# AM13E230x register map
Vendor: Texas Instruments; File version: Revised: 2025-12-26 17:30:06
CPU: CM33 r0p0, little endian, MPU, FPU, 4 interrupt priority bits
Registers are 32-bit, read-write, reset 0x0 unless marked. A register's access mark holds for its fields unless they carry their own. Offsets are from the block's base; [hi:lo] are bit positions; 'fields as' and 'values as' point back to an identical list.

## FACTORYREGION — Factory-programmed device data (read-only)
Base 0x60111000
0x00 TRACEID ro — Defined by TI, during ATE, based on wafer
  [31:0] DATA
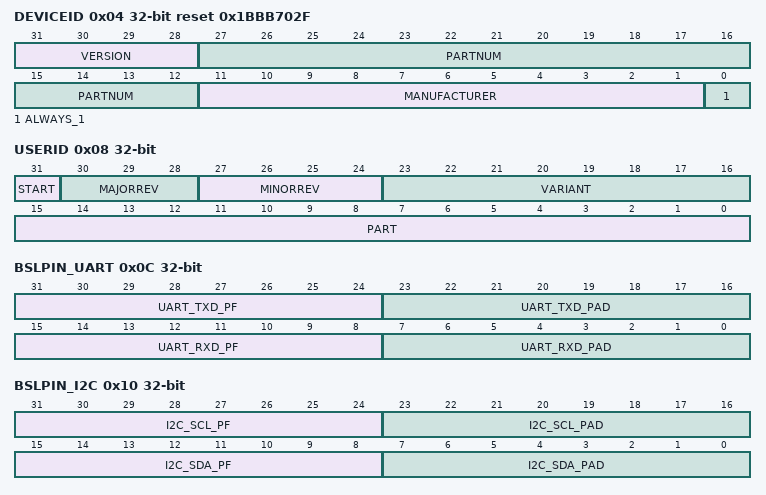
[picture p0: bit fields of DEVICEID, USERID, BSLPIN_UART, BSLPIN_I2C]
0x04 DEVICEID ro reset 0x1BBB702F
  [31:28] VERSION — Revision of the device. This field should change each time that the logic or mask set of the device is revised.
  [27:12] PARTNUM — Part number of the device.
  [11:1] MANUFACTURER — TI's JEDEC bank and company code, which is: 00000010111b
  [0] ALWAYS_1 — This is always 1
0x08 USERID ro — Defined by TI, depending on device spin
  [31] START
  [30:28] MAJORREV — Monotonic increasing value indicating a new revision of the SKU significant enough that users of the device may have to revise PCB or or software design
  [27:24] MINORREV — Monotonic increasing value indicating a new revision of the SKU that preserves compatibility with lesser minorrev values. New capability may be introduced such that lesser minorrev numbers may not be compatible with greater if the new capability is used.
  [23:16] VARIANT — Bit pattern uniquely identifying a variant of a part. This is used to indicate memory or package variations of the same part number. This number shall be selected at random among the remaining numbers for the relevant combination of IDCODE.device and USERCODE.part such that the order of creation cannot be inferred by the number. The variant number does not encode specifics of the variant directly.
  [15:0] PART — Bit pattern that uniquely identifying a part. This is used to identify the specific part based on the die identified in DEVICEID.device. This number shall be selected at random among the remaining numbers for DEVICEID.device such that the order of creation cannot be inferred by the number. This value does not encode the part number directly.
0x0C BSLPIN_UART ro — BSL UART Pin Configuration
  [31:24] UART_TXD_PF — UART TXD Pin Function Selection Value
  [23:16] UART_TXD_PAD — UART TXD Pin used by BSL
  [15:8] UART_RXD_PF — UART RXD Pin Function Selection Value
  [7:0] UART_RXD_PAD — UART RXD Pad used by BSL
0x10 BSLPIN_I2C ro — BSL I2C Pin Configuration
  [31:24] I2C_SCL_PF — I2C SCL Pin Function Selection Value
  [23:16] I2C_SCL_PAD — I2C SCL Pin used by BSL
  [15:8] I2C_SDA_PF — I2C SDA Pin Function Selection Value
  [7:0] I2C_SDA_PAD — I2C SDA Pin used by BSL
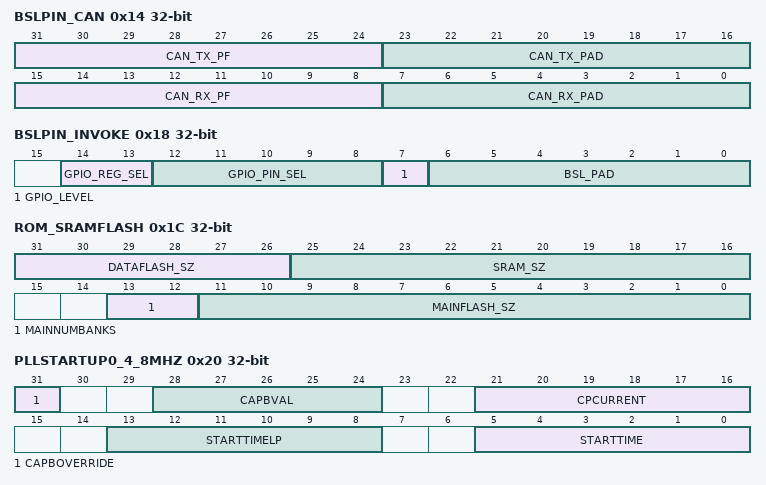
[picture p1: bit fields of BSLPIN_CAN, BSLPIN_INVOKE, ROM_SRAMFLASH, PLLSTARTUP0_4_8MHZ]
0x14 BSLPIN_CAN ro — BSL CAN Pin Configuration
  [31:24] CAN_TX_PF — MCAN TX Pin Function Selection Value
  [23:16] CAN_TX_PAD — MCAN TX Pin used by BSL
  [15:8] CAN_RX_PF — MCAN RX Pin Function Selection Value
  [7:0] CAN_RX_PAD — MCAN RX Pin used by BSL
0x18 BSLPIN_INVOKE ro — BSL Pin Invocation Configuration
  [14:13] GPIO_REG_SEL — GPIO Module Selection
  [12:8] GPIO_PIN_SEL — GPIO Pin Number in GPIO Module
  [7] GPIO_LEVEL — GPIO Level Configuration for BSL Invocation
  [6:0] BSL_PAD — BSL Invocation Pin Number
0x1C ROM_SRAMFLASH ro
  [31:26] DATAFLASH_SZ — The encoding of the field is that the value of the field is an integer to be interpreted as number of KBs. For eg: if the value of the field id 4, then it is 4KB, if the value is 32, then 32KB, and so on.
  [25:16] SRAM_SZ — The encoding of the field is that the value of the field is an integer to be interpreted as number of KBs. For eg: if the value of the field id 4, then it is 4KB, if the value is 32, then 32KB, and so on.
  [13:12] MAINNUMBANKS — Defines the number of main flash banks
  [11:0] MAINFLASH_SZ — The encoding of the field is that the value of the field is an integer to be interpreted as number of KBs. For eg: if the value of the field id 4, then it is 4KB, if the value is 32, then 32KB, and so on.
0x20 PLLSTARTUP0_4_8MHZ ro
  [31] CAPBOVERRIDE — Override Enable For Cap B
    0=DISABLE; 1=ENABLE
  [28:24] CAPBVAL — Override Value for Cap B
  [21:16] CPCURRENT — Charge Pump Current
  [13:8] STARTTIMELP — Startup time from Low Power Exit to Locked Clock in resolution of 1usec
  [5:0] STARTTIME — Startup time from Enable to Locked Clock in resolution of 1usec
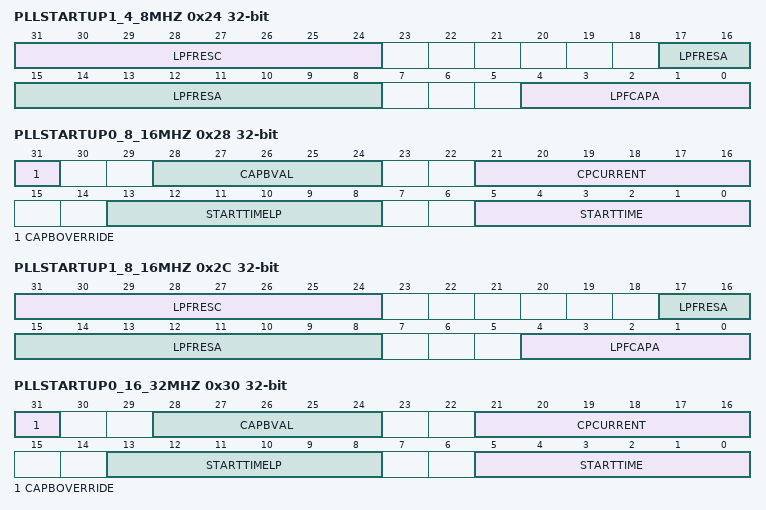
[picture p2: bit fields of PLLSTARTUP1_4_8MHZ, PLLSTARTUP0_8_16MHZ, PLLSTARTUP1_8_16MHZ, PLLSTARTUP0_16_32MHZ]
0x24 PLLSTARTUP1_4_8MHZ ro
  [31:24] LPFRESC — Loop Filter Res C
  [17:8] LPFRESA — Loop Filter Res A
  [4:0] LPFCAPA — Loop Filter Cap A
0x28 PLLSTARTUP0_8_16MHZ ro
  fields as PLLSTARTUP0_4_8MHZ
0x2C PLLSTARTUP1_8_16MHZ ro
  fields as PLLSTARTUP1_4_8MHZ
0x30 PLLSTARTUP0_16_32MHZ ro
  fields as PLLSTARTUP0_4_8MHZ
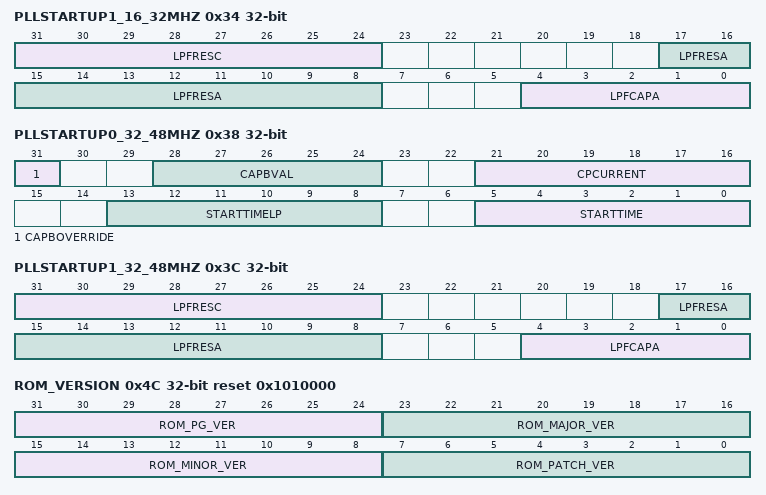
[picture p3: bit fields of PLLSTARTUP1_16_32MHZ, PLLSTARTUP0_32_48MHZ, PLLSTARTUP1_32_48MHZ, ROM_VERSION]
0x34 PLLSTARTUP1_16_32MHZ ro
  fields as PLLSTARTUP1_4_8MHZ
0x38 PLLSTARTUP0_32_48MHZ ro
  fields as PLLSTARTUP0_4_8MHZ
0x3C PLLSTARTUP1_32_48MHZ ro
  fields as PLLSTARTUP1_4_8MHZ
0x40 TEMP_SENSE0 ro
  [31:0] DATA
0x44 BOOTCRC ro
  [31:0] DATA
0x4C ROM_VERSION ro reset 0x1010000
  [31:24] ROM_PG_VER, [23:16] ROM_MAJOR_VER, [15:8] ROM_MINOR_VER, [7:0] ROM_PATCH_VER
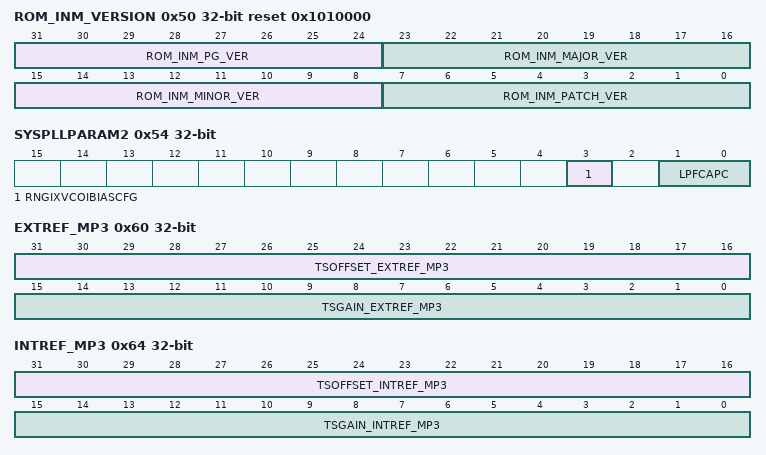
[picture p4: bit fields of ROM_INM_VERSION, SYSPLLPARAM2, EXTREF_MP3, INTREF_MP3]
0x50 ROM_INM_VERSION ro reset 0x1010000
  [31:24] ROM_INM_PG_VER, [23:16] ROM_INM_MAJOR_VER, [15:8] ROM_INM_MINOR_VER, [7:0] ROM_INM_PATCH_VER
0x54 SYSPLLPARAM2 ro
  [3] RNGIXVCOIBIASCFG, [1:0] LPFCAPC
0x58 SYSPLLLDOCTL ro
  [15:0] LDOCTLLOWV
0x5C SYSPLLLDOPROG ro
  [2:0] LDOVOUTPROGLOWV
0x60 EXTREF_MP3 ro — External Reference MP3 Temp Sense
  [31:16] TSOFFSET_EXTREF_MP3 — Temperature sensor offset is recorded here
  [15:0] TSGAIN_EXTREF_MP3 — Temperature sensor gain is recorded here
0x64 INTREF_MP3 ro — Internal Refernce Temp Sene
  [31:16] TSOFFSET_INTREF_MP3 — Temperature sensor offset is recorded here
  [15:0] TSGAIN_INTREF_MP3 — Temperature sensor gain is recorded here
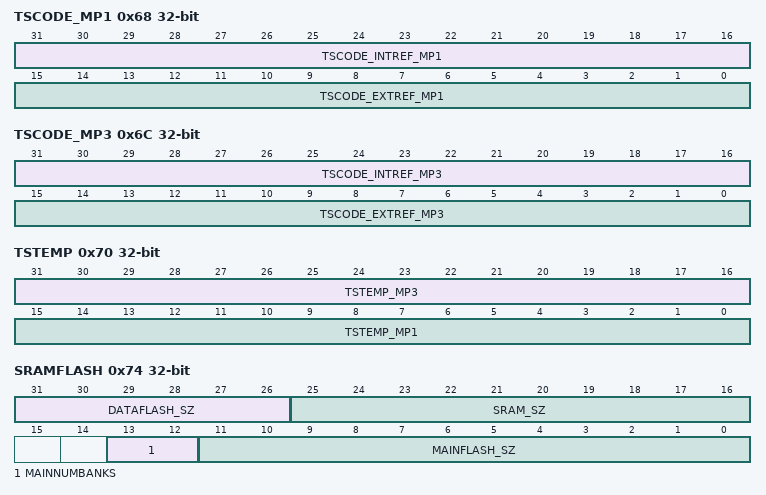
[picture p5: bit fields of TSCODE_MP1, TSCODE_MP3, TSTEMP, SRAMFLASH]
0x68 TSCODE_MP1 ro — Tempsense Code MP1
  [31:16] TSCODE_INTREF_MP1 — Temperature sensor value at 30C stored at this location
  [15:0] TSCODE_EXTREF_MP1 — Temperature sensor value at 30C stored at this location
0x6C TSCODE_MP3 ro — Tempsense code MP3
  [31:16] TSCODE_INTREF_MP3 — Temperature sensor value at 125C stored at this location
  [15:0] TSCODE_EXTREF_MP3 — Temperature sensor value at 125C stored at this location
0x70 TSTEMP ro — Temperature sense TEMP
  [31:16] TSTEMP_MP3 — Test temperature (125C) is recorded here
  [15:0] TSTEMP_MP1 — Test temperature (30C) is recorded here
0x74 SRAMFLASH ro — Number of banks , sram size and flash size
  [31:26] DATAFLASH_SZ — The encoding of the field is that the value of the field is an integer to be interpreted as number of KBs. For eg: if the value of the field id 4, then it is 4KB, if the value is 32, then 32KB, and so on.
  [25:16] SRAM_SZ — The encoding of the field is that the value of the field is an integer to be interpreted as number of KBs.
  [13:12] MAINNUMBANKS — Defines the number of main flash banks
  [11:0] MAINFLASH_SZ — For eg: if the value of the field id 4, then it is 4KB, if the value is 32, then 32KB, and so on.
